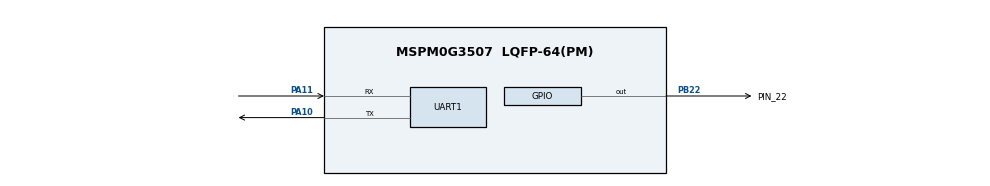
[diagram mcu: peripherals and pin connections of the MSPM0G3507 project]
/**
 * These arguments were used when this file was generated. They will be automatically applied on subsequent loads
 * via the GUI or CLI. Run CLI with '--help' for additional information on how to override these arguments.
 * @cliArgs --device "MSPM0G350X" --part "Default" --package "LQFP-64(PM)" --product "mspm0_sdk@2.10.00.04"
 * @v2CliArgs --device "MSPM0G3507" --package "LQFP-64(PM)" --product "mspm0_sdk@2.10.00.04"
 * @versions {"tool":"1.27.1+4634"}
 */

/**
 * Import the modules used in this configuration.
 */
const GPIO    = scripting.addModule("/ti/driverlib/GPIO", {}, false);
const GPIO1   = GPIO.addInstance();
const GPIO2   = GPIO.addInstance();
const SYSCTL  = scripting.addModule("/ti/driverlib/SYSCTL");
const SYSTICK = scripting.addModule("/ti/driverlib/SYSTICK");
const UART    = scripting.addModule("/ti/driverlib/UART", {}, false);
const UART1   = UART.addInstance();

/**
 * Write custom configuration values to the imported modules.
 */
const divider9       = system.clockTree["UDIV"];
divider9.divideValue = 2;

const mux2       = system.clockTree["CANCLKMUX"];
mux2.inputSelect = "CANCLKMUX_PLLCLK1_OUT";

const mux4       = system.clockTree["EXHFMUX"];
mux4.inputSelect = "EXHFMUX_XTAL";

const mux8       = system.clockTree["HSCLKMUX"];
mux8.inputSelect = "HSCLKMUX_SYSPLL2X";

const mux12       = system.clockTree["SYSPLLMUX"];
mux12.inputSelect = "zSYSPLLMUX_HFCLK";

const pinFunction4     = system.clockTree["HFXT"];
pinFunction4.inputFreq = 40;
pinFunction4.enable    = true;

GPIO1.$name                         = "LED";
GPIO1.port                          = "PORTB";
GPIO1.associatedPins[0].ioStructure = "SD";
GPIO1.associatedPins[0].$name       = "PIN_22";
GPIO1.associatedPins[0].pin.$assign = "PB22";

const Board = scripting.addModule("/ti/driverlib/Board", {}, false);

GPIO2.$name                   = "GPIO_GRP_0";
GPIO2.associatedPins[0].$name = "PIN_0";

SYSCTL.forceDefaultClkConfig = true;
SYSCTL.clockTreeEn           = true;

SYSTICK.periodEnable      = true;
SYSTICK.interruptEnable   = true;
SYSTICK.period            = 80000;
SYSTICK.interruptPriority = "3";
SYSTICK.systickEnable     = true;

UART1.$name                            = "sys_uart";
UART1.targetBaudRate                   = 115200;
UART1.peripheral.rxPin.$assign         = "PA11";
UART1.peripheral.txPin.$assign         = "PA10";
UART1.txPinConfig.$name                = "ti_driverlib_gpio_GPIOPinGeneric0";
UART1.txPinConfig.direction            = scripting.forceWrite("OUTPUT");
UART1.txPinConfig.hideOutputInversion  = scripting.forceWrite(false);
UART1.txPinConfig.onlyInternalResistor = scripting.forceWrite(false);
UART1.txPinConfig.passedPeripheralType = scripting.forceWrite("Digital");
UART1.txPinConfig.enableConfig         = true;
UART1.rxPinConfig.$name                = "ti_driverlib_gpio_GPIOPinGeneric1";
UART1.rxPinConfig.hideOutputInversion  = scripting.forceWrite(false);
UART1.rxPinConfig.onlyInternalResistor = scripting.forceWrite(false);
UART1.rxPinConfig.passedPeripheralType = scripting.forceWrite("Digital");
UART1.rxPinConfig.enableConfig         = true;

/**
 * Pinmux solution for unlocked pins/peripherals. This ensures that minor changes to the automatic solver in a future
 * version of the tool will not impact the pinmux you originally saw.  These lines can be completely deleted in order to
 * re-solve from scratch.
 */
pinFunction4.peripheral.$suggestSolution           = "SYSCTL";
pinFunction4.peripheral.hfxInPin.$suggestSolution  = "PA5";
pinFunction4.peripheral.hfxOutPin.$suggestSolution = "PA6";
Board.peripheral.$suggestSolution                  = "DEBUGSS";
Board.peripheral.swclkPin.$suggestSolution         = "PA20";
Board.peripheral.swdioPin.$suggestSolution         = "PA19";
GPIO2.associatedPins[0].pin.$suggestSolution       = "PB13";
UART1.peripheral.$suggestSolution                  = "UART0";
